# PIC32MK1024GPK064 device description
Architecture: MIPS; Family: PIC32MK; Series: PIC32MK
Registers are 32-bit, read-write, no defined reset value unless marked. A register's access mark holds for its fields unless they carry their own. Offsets are from the block's base; [hi:lo] are bit positions; {n}, {i} and the like mark numbered series; 'fields as' and 'values as' point back to an identical list.

## ADCHS
Instances: ADCHS 0x1f887000 in periph_pb5_std
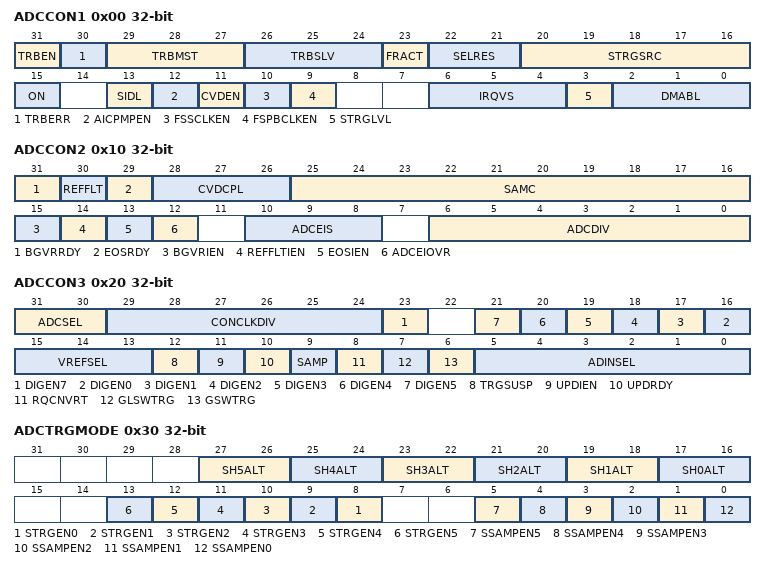
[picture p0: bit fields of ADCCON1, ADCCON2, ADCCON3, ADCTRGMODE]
0x00 ADCCON1 — ADC Control Register 1
  [31] TRBEN — Turbo Channel Enable bit
    1=Enable the Turbo channel; 0=Disable the Turbo channel
  [30] TRBERR — Turbo Channel Error Status bit
    1=An error occurred while setting the Turbo channel and Turbo channel function to be disabled regardless of the TRBEN bit being set to 1; 0=Turbo channel error did not occur
  [29:27] TRBMST — Turbo Master ADCx bits
    {v}=ADC{v} (v=0..5)
  [26:24] TRBSLV — Turbo Slave ADCx bits
    {v}=ADC{v} (v=0..5)
  [23] FRACT — Fractional Data Output Format bit
    1=Fractional; 0=Integer
  [22:21] SELRES — Shared ADC7 Resolution bits
    3=12 bits (default); 2=10 bits; 1=8 bits; 0=6 bits
  [20:16] STRGSRC — Scan Trigger Source Select bits
    30=PWM Generator 12 trigger (Motor Control only); 29=PWM Generator 11 trigger (Motor Control only); 28=PWM Generator 10 trigger (Motor Control only); {v}=PWM Generator {v-23} Current-Limit (Motor Control only) (v=24..27); 23=PWM Generator 9 trigger; 22=PWM Generator 8 trigger; 21=PWM Generator 7 trigger; 20=CTMU trip; {v}=Output Compare {v-15} period end (v=16..19); {v}=PWM Generator {v-9} trigger (Motor Control only) (v=10..15); 9=Secondary PWM time base (Motor Control only); 8=Primary PWM time base (Motor Control only); 7=General Purpose Timer5; 6=General Purpose Timer3; 5=General Purpose Timer1; 4=INT0; 3=Scan trigger; 2=Software level trigger; 1=Software edge trigger; 0=No Trigger
  [15] ON — ADC Module Enable bit
    1=ADC module is enabled; 0=ADC module is disabled
  [13] SIDL — Stop in Idle Mode bit
    1=Discontinue module operation when device enters Idle mode; 0=Continue module operation in Idle mode
  [12] AICPMPEN — Analog Input Charge Pump Enable bit
    1=Analog input charge pump is enabled; 0=Analog input charge pump is disabled (default)
  [11] CVDEN — Capacitive Voltage Division Enable bit
    1=CVD operation is enabled; 0=CVD operation is disabled
  [10] FSSCLKEN — Fast Synchronous System Clock to ADC Control Clock bit
    1=Fast synchronous system clock to ADC control clock is enabled; 0=Fast synchronous system clock to ADC control clock is disabled
  [9] FSPBCLKEN — Fast Synchronous Peripheral Clock to ADC Control Clock bit
    1=Fast synchronous peripheral clock to ADC control clock is enabled; 0=Fast synchronous peripheral clock to ADC control clock is disabled
  [6:4] IRQVS — Interrupt Vector Shift bits
    {v}=Shift x left {v} bit position (v=0..7)
  [3] STRGLVL — Scan Trigger High Level/Positive Edge Sensitivity bit
    1=Scan trigger is high level sensitive. Once STRIG mode is selected the scan trigger will continue for all selected analog inputs; 0=Scan trigger is positive edge sensitive. Once STRIG mode is selected only a single scan trigger will be generated which will complete the scan of all selected analog inputs. (TRGSRCx in the ADCTRGx register)
  [2:0] DMABL — DMA to System RAM Buffer Length Size bits
    7=Allocates 128 locations in system memory to each analog input; 6=Allocates 64 locations in system memory to each analog input; 5=Allocates 32 locations in system memory to each analog input; 4=Allocates 16 locations in system memory to each analog input; 3=Allocates 8 locations in system memory to each analog input; 2=Allocates 4 locations in system memory to each analog input; 1=Allocates 2 locations in system memory to each analog input; 0=Allocates 1 location in system memory to each analog input
0x10 ADCCON2 — ADC Control Register 2
  [31] BGVRRDY — Band Gap Voltage/ADC Reference Voltage Status bit
    1=Both band gap voltage and ADC reference voltages (Vref) are ready; 0=Either or both band gap voltage and ADC reference voltages (Vref) are not ready
  [30] REFFLT — Band Gap/ Vref / AVdd BOR Fault Status bit
    1=Fault in band gap or the Vref voltage while the ON bit (ADCCON1) was set. Most likely a band gap or Vref fault will be caused by a BOR of the analog Vdd supply.; 0=Band gap and Vref voltage are working properly
  [29] EOSRDY — End of Scan Interrupt Status bit
    1=All analog inputs are considered for scanning through the scan trigger (all analog inputs specified in the ADCCSS1 and ADCCSS2 registers) have completed scanning; 0=Scanning has not completed
  [28:26] CVDCPL — Capacitor Voltage Divider Setting bits
    7=7 * 2.5 pF = 17.5 pF; 6=6 * 2.5 pF = 15 pF; 5=5 * 2.5 pF = 12.5 pF; 4=4 * 2.5 pF = 10 pF; 3=3 * 2.5 pF = 7.5 pF; 2=2 * 2.5 pF = 5 pF; 1=1 * 2.5 pF = 2.5 pF; 0=0 * 2.5 pF = 0 pF
  [25:16] SAMC — Sample Time for the Shared ADC (ADC7) bits
    0x3ff=1025 Tad; 1=3 Tad; 0=2 Tad
  [15] BGVRIEN — Band Gap/ Vref Voltage Ready Interrupt Enable bit
    1=Interrupt will be generated when the BGVRDDY bit is set; 0=No interrupt is generated when the BGVRRDY bit is set
  [14] REFFLTIEN — Band Gap/ Vref Voltage Fault Interrupt Enable bit
    1=Interrupt will be generated when the REFFLT bit is set; 0=No interrupt is generated when the REFFLT bit is set
  [13] EOSIEN — End of Scan Interrupt Enable bit
    1=Interrupt will be generated when EOSRDY bit is set; 0=No interrupt is generated when the EOSRDY bit is set
  [12] ADCEIOVR — Early Interrupt Request Override bit
    1=Early interrupt generation is overridden and interrupt generation is controlled by the ADCGIRQEN1 and ADCGIRQEN2 registers; 0=Early interrupt generation is not overridden and interrupt generation is controlled by the ADCEIEN1 and ADCEIEN2 registers
  [10:8] ADCEIS — Shared ADC Early Interrupt Select bits
    {v}=The data ready interrupt is generated {v+1} ADC clocks prior to end of conversion (v=2..7); 1=The data ready interrupt is generated 2 ADC module clocks prior to end of conversion; 0=The data ready interrupt is generated 1 ADC module clock prior to end of conversion
  [6:0] ADCDIV — Shared ADC Clock Divider bits
    127=254 * Tq = Tad; 3=6 * Tq = Tad; 2=4 * Tq = Tad; 1=2 * Tq = Tad
0x20 ADCCON3 — ADC Control Register 3
  [31:30] ADCSEL — Analog-to-Digital Clock Source bits
    3=SYSCLK; 2=REFCLK3; 1=FRC; 0=SYSCLK
  [29:24] CONCLKDIV — Analog-to-Digital Control Clock Divider bits
    63=126 * Tclk = Tq; 3=6 * Tclk = Tq; 2=4 * Tclk = Tq; 1=2 * Tclk = Tq; 0=Tclk = Tq
  [23] DIGEN7 — Shared ADC (ADC7) Digital Enable bit
    1=ADC7 is digital enabled; 0=ADC7 is digital disabled
  [n+16] DIGEN{n} (n=0..5) — ADC{n} Digital Enable bit
    1=ADC{n} is digital enabled (required for active operation); 0=ADC{n} is digital disabled (power-saving mode)
  [15:13] VREFSEL — Voltage Reference Input Selection bits
    3=ADC VREFH is VREF+, ADC VREFL is VREF-; 2=ADC VREFH is AVDD, ADC VREFL is VREF-; 1=ADC VREFH is VREF+, ADC VREFL is AVSS; 0=ADC VREFH is AVDD, ADC VREFL is AVSS
  [12] TRGSUSP — Trigger Suspend bit
    1=Triggers are blocked from starting a new analog-to-digital conversion; 0=Triggers are not blocked
  [11] UPDIEN — Update Ready Interrupt Enable bit
    1=Interrupt will be generated when the UPDRDY bit is set by hardware; 0=No interrupt is generated
  [10] UPDRDY — ADC Update Ready Status bit
    1=ADC SFRs can be updated; 0=ADC SFRs cannot be updated
  [9] SAMP — Shared ADC7 Analog Input Sampling Enable bit
    1=The ADC S&H amplifier is sampling; 0=The ADC S&H amplifier is holding
  [8] RQCNVRT — Individual ADC Input Conversion Request bit
    1=Trigger the conversion of the selected ADC input as specified by the ADINSEL bits; 0=Do not trigger the conversion
  [7] GLSWTRG — Global Level Software Trigger bit
    1=Trigger conversion for ADC inputs that have selected the GLSWTRG bit as the trigger signal; 0=Do not trigger an analog-to-digital conversion
  [6] GSWTRG — Global Software Trigger bit
    1=Trigger conversion for ADC inputs that have selected the GSWTRG bit as either through the associated TRGSRC bits in the ADCTRGx registers or through the STRGSRC<4:0> bits in the ADCCON1 register the trigger signal; 0=Do not trigger an analog-to-digital conversion
  [5:0] ADINSEL — Analog Input Select bits
    53=CTMU Temperature Sensor (internal AN53); 52=VBAT/2 (internal AN52); 50=IVref 1.2V (internal AN50); {v}=AN{v} (v=45..49); {v}=AN{v} (v=33..41); {v}=AN{v} (v=0..27)
0x30 ADCTRGMODE — ADC Triggering Mode for Dedicated ADC Register
  [27:26] SH5ALT — ADC5 Analog Input Select bit
    3=AN25; 2=AN6; 1=AN2; 0=AN5
  [25:24] SH4ALT — ADC4 Analog Input Select bit
    3=AN0; 2=AN9; 1=AN1; 0=AN4
  [23:22] SH3ALT — ADC3 Analog Input Select bit
    3=AN26; 2=AN8; 1=AN0; 0=AN3
  [21:20] SH2ALT — ADC2 Analog Input Select bit
    3=AN25; 2=AN6; 1=AN5; 0=AN2
  [19:18] SH1ALT — ADC1 Analog Input Select bit
    3=AN0; 2=AN7; 1=AN4; 0=AN1
  [17:16] SH0ALT — ADC0 Analog Input Select bit
    3=AN24; 2=AN5; 1=AN3; 0=AN0
  [n+8] STRGEN{n} (n=0..5) — ADC{n} Presynchronized Triggers bit
    1=ADC{n} uses presynchronized triggers; 0=ADC{n} does not use presynchronized triggers
  [5] SSAMPEN5 — ADC5 Synchronous Sampling bit
    1=ADC5 uses synchronous sampling for the first sample after being idle or disabled; 0=ADC5 does not use synchronous sampling
  [4] SSAMPEN4 — ADC4 Synchronous Sampling bit
    1=ADC4 uses synchronous sampling for the first sample after being idle or disabled; 0=ADC4 does not use synchronous sampling
  [3] SSAMPEN3 — ADC3 Synchronous Sampling bit
    1=ADC3 uses synchronous sampling for the first sample after being idle or disabled; 0=ADC3 does not use synchronous sampling
  [2] SSAMPEN2 — ADC2Synchronous Sampling bit
    1=ADC2 uses synchronous sampling for the first sample after being idle or disabled; 0=ADC2 does not use synchronous sampling
  [1] SSAMPEN1 — ADC1 Synchronous Sampling bit
    1=ADC1 uses synchronous sampling for the first sample after being idle or disabled; 0=ADC1 does not use synchronous sampling
  [0] SSAMPEN0 — ADC0 Synchronous Sampling bit
    1=ADC0 uses synchronous sampling for the first sample after being idle or disabled; 0=ADC0 does not use synchronous sampling
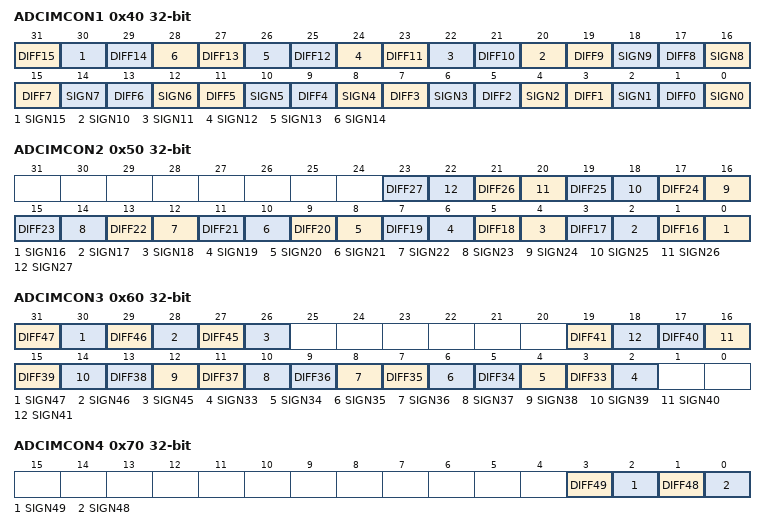
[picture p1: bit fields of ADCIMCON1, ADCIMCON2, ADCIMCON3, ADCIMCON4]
0x40 ADCIMCON1 — ADC Input Mode Control Register 1
  [2n+1] DIFF{n} (n=9..15) — AN{n} Mode bit
    1=Selects AN{n} differential input pair as AN{n}+ and AN1-; 0=AN{n} is using Single-ended mode
  [30] SIGN15 — NO_SUCH_FIELD
    1=AN15 is using Signed Data mode; 0=AN15 is using Unsigned Data mode
  [2n] SIGN{n} (n=0..14) — AN{n} Signed Data Mode bit
    1=AN{n} is using Signed Data mode; 0=AN{n} is using Unsigned Data mode
  [17] DIFF8 — AN 8 Mode bit
    1=Selects AN8 differential input pair as AN8+ and AN1-; 0=AN8 is using Single-ended mode
  [15] DIFF7 — AN7 Mode bit
    1=Selects AN7 differential input pair as AN7+ and AN1-; 0=AN7 is using Single-ended mode
  [13] DIFF6 — AN6 Mode bit
    1=Selects AN6 differential input pair as AN6+ and AN1-; 0=AN6 is using Single-ended mode
  [11] DIFF5 — AN5 Mode bit
    1=Selects AN5 differential input pair as AN5+ and AN11-; 0=AN5 is using Single-ended mode
  [9] DIFF4 — AN4 Mode bit
    1=Selects AN4 differential input pair as AN4+ and AN10-; 0=AN4 is using Single-ended mode
  [7] DIFF3 — AN3 Mode bit
    1=Selects AN3 differential input pair as AN3+ and AN27-; 0=AN3 is using Single-ended mode
  [5] DIFF2 — AN2 Mode bit
    1=Selects AN2 differential input pair as AN2+ and AN8-; 0=AN2 is using Single-ended mode
  [3] DIFF1 — AN1 Mode bit
    1=Selects AN1 differential input pair as AN1+ and AN7-; 0=AN1 is using Single-ended mode
  [1] DIFF0 — AN0 Mode bit
    1=Selects AN0 differential input pair as AN0+ and AN6-; 0=AN0 is using Single-ended mode
0x50 ADCIMCON2 — ADC Input Mode Control Register 2
  [2n-31] DIFF{n} (n=16..27) — AN{n} Mode bit
    1=Selects AN{n} differential pair input as AN{n}+ and AN1-; 0=AN{n} is using Single-ended mode
  [2n-32] SIGN{n} (n=16..27) — AN{n} Signed Data Mode bit
    values as ADCIMCON1.SIGN0
0x60 ADCIMCON3 — ADC Input Mode Control Register 3
  [31] DIFF47 — AN47 Mode bit
    1=Selects AN47 differential input pair as AN47+ and AN1-; 0=AN47 is using Single-ended mode
  [30] SIGN47 — AN47 Signed Data Mode bit
    1=AN41 is using Signed Data mode; 0=AN41 is using Unsigned Data mode
  [29] DIFF46 — AN46 Mode bit
    1=Selects AN46 differential input pair as AN46+ and AN1-; 0=AN41 is using Single-ended mode
  [28] SIGN46 — AN45 Signed Data Mode bit
    1=AN46 is using Signed Data mode; 0=AN46 is using Unsigned Data mode
  [27] DIFF45 — AN45 Mode bit
    1=Selects AN45 differential input pair as AN45+ and AN1-; 0=AN45 is using Single-ended mode
  [26] SIGN45 — NO_SUCH_FIELD
    1=AN45 is using Signed Data mode; 0=AN45 is using Unsigned Data mode
  [2n-63] DIFF{n} (n=33..41) — AN{n} Mode bit
    values as ADCIMCON1.DIFF9
  [2n-64] SIGN{n} (n=33..41) — AN{n} Signed Data Mode bit
    values as ADCIMCON1.SIGN0
0x70 ADCIMCON4 — ADC Input Mode Control Register 4
  [3] DIFF49 — AN49 Mode bit
    1=Selects AN49 differential input pair as AN49+ and AN1-; 0=AN49 is using Single-ended mode
  [2] SIGN49 — AN41 Signed Data Mode bit
    1=AN49 is using Signed Data mode; 0=AN49 is using Unsigned Data mode
  [1] DIFF48 — AN48 Mode bit
    1=Selects AN40 differential input pair as AN48+ and AN1-; 0=AN48 is using Single-ended mode
  [0] SIGN48 — AN48 Signed Data Mode bit
    1=AN48 is using Signed Data mode; 0=AN48 is using Unsigned Data mode
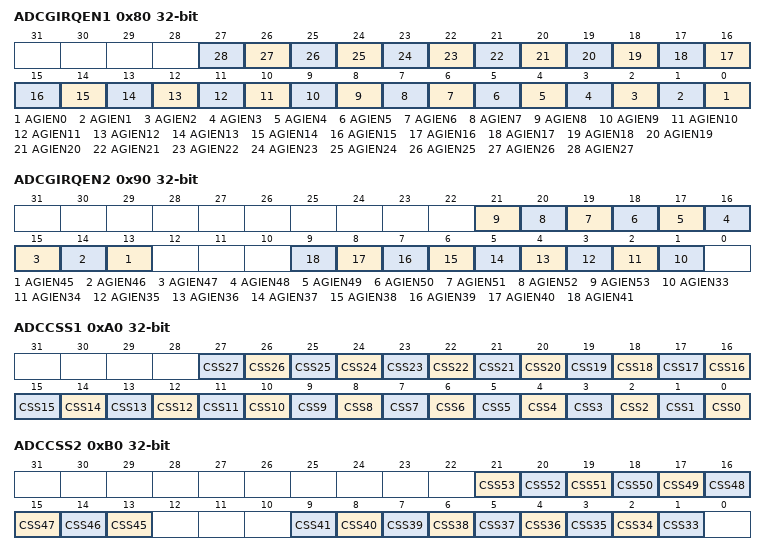
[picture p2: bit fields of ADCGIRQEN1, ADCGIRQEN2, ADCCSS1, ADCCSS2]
0x80 ADCGIRQEN1 — ADC Global Interrupt Enable Register 1
  [all] fields
    1=Interrupts are enabled for the selected analog input. The interrupt is generated after the converted data is ready (indicated by the AIRDYx bit of the ADCDSTAT1 register); 0=Interrupts are disabled
  [n] AGIEN{n} (n=0..27) — ADC Global Interrupt Enable bit
0x90 ADCGIRQEN2 — ADC Global Interrupt Enable Register 2
  [all] fields
    values as the fields of ADCGIRQEN1
  [n-32] AGIEN{n} (n=45..53) — ADC Global Interrupt Enable bit
  [n-32] AGIEN{n} (n=33..41) — ADC Global Interrupt Enable bit
0xA0 ADCCSS1 — ADC Common Scan Select Register 1
  [all] fields
    1=Select ANx for input scan (i.e.ANx = CSSx and scan is sequential starting with the lowest to highest enabled CSSx analog input pin); 0=Skip ANx for input scan
  [n] CSS{n} (n=0..27) — Analog Common Scan Select bits
0xB0 ADCCSS2 — ADC Common Scan Select Register 2
  [all] fields
    values as the fields of ADCCSS1
  [n-32] CSS{n} (n=45..53) — Analog Common Scan Select bits
  [n-32] CSS{n} (n=33..41) — Analog Common Scan Select bits
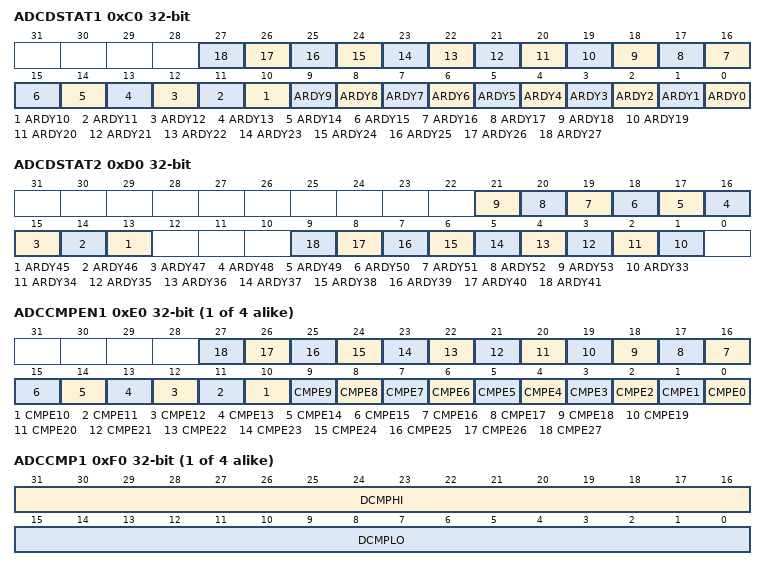
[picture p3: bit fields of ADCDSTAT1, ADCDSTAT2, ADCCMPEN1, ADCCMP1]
0xC0 ADCDSTAT1 ro — ADC Data Ready Status Register 1
  [all] fields
    1=This bit is set when converted data is ready in the data register; 0=This bit is cleared when the associated data register is read
  [n] ARDY{n} (n=0..27) — Conversion Data Ready for Corresponding Analog Input Ready bits
0xD0 ADCDSTAT2 ro — ADC Data Ready Status Register 2
  [all] fields
    values as the fields of ADCDSTAT1
  [n-32] ARDY{n} (n=45..53) — Conversion Data Ready for Corresponding Analog Input Ready bits
  [n-32] ARDY{n} (n=33..41) — Conversion Data Ready for Corresponding Analog Input Ready bits
{0xC0+0x20*i} ADCCMPEN{i} (i=1..4) — ADC Digital Comparator 'x' Enable Register ('x' = 1 through 4)
  [n] CMPE{n} (n=0..27)
{0xD0+0x20*i} ADCCMP{i} (i=1..4) — ADC Digital Comparator
  [31:16] DCMPHI, [15:0] DCMPLO
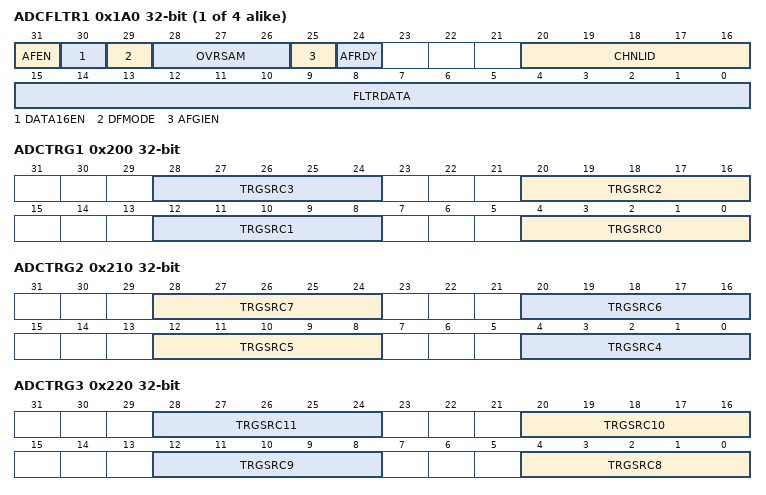
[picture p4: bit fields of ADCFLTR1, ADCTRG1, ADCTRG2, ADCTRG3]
{0x190+0x10*i} ADCFLTR{i} (i=1..4) — ADC Digital Filter Register
  [31] AFEN — Digital Filter 'x' Enable bit
    1=Digital filter is enabled; 0=Digital filter is disabled and the AFRDY status bit is cleared
  [30] DATA16EN — Filter Significant Data Length bit
    1=All 16 bits of the filter output data are significant; 0=Only the first 12 bits are significant
  [29] DFMODE — ADC Filter Mode bit
    1=Filter x works in Averaging mode; 0=Filter x works in Oversampling Filter mode (default)
  [28:26] OVRSAM — Oversampling Filter Ratio bits
    7=(If DFMODE is 0) 128 samples (shift sum 3 bits to right output data is in 15.1 format) / (If DFMODE is 1) 256 samples (256 samples to be averaged); 6=(If DFMODE is 0) 32 samples (shift sum 2 bits to right output data is in 14.1 format) / (If DFMODE is 1) 128 samples (128 samples to be averaged); 5=(If DFMODE is 0) 8 samples (shift sum 1 bit to right output data is in 13.1 format) / (If DFMODE is 1) 64 samples (64 samples to be averaged); 4=(If DFMODE is 0) 2 samples (shift sum 0 bits to right output data is in 12.1 format) / (If DFMODE is 1) 32 samples (32 samples to be averaged); 3=(If DFMODE is 0) 256 samples (shift sum 4 bits to right output data is 16 bits) / (If DFMODE is 1) 16 samples (16 samples to be averaged); 2=(If DFMODE is 0) 64 samples (shift sum 3 bits to right output data is 15 bits) / (If DFMODE is 1) 8 samples (8 samples to be averaged); 1=(If DFMODE is 0) 16 samples (shift sum 2 bits to right output data is 14 bits) / (If DFMODE is 1) 4 samples (4 samples to be averaged); 0=(If DFMODE is 0) 4 samples (shift sum 1 bit to right output data is 13 bits) / (If DFMODE is 1) 2 samples (2 samples to be averaged)
  [25] AFGIEN — Digital Filter 'x' Interrupt Enable bit
    1=Digital filter interrupt is enabled and is generated by the AFRDY status bit; 0=Digital filter is disabled
  [24] AFRDY — Digital Filter 'x' Data Ready Status bit
    1=Data is ready in the FLTRDATA bits; 0=Data is not ready
  [20:16] CHNLID — Digital Filter Analog Input Selection bits
    {v}=AN{v} input (v=24..27); {v}=AN{v}(1) input (v=20..23); {v}=AN{v} input (v=6..19); {v}=ADC{v} Module (v=0..5)
  [15:0] FLTRDATA
0x200 ADCTRG1 — ADC Trigger Source 1 Register
  [all] fields
    30=PWM Generator 12 trigger (Motor control only); 29=PWM Generator 11 trigger (Motor control only); 28=PWM Generator 10 trigger (Motor control only); {v}=PWM Generator {v-23} Current-Limit (Motor Control Variants Only) (v=24..27); 23=PWM Generator 9 trigger; 22=PWM Generator 8 trigger; 21=PWM Generator 7 trigger; 20=CTMU trip; {v}=Output Compare {v-15} period end (v=16..19); {v}=PWM Generator {v-9} trigger (Motor Control Variants Only) (v=10..15); 9=Secondary Special time base (Motor Control Variants Only); 8=Primary Special Event time base (Motor Control Variants Only); 7=General Purpose Timer5; 6=General Purpose Timer3; 5=General Purpose Timer1; 4=INT0; 3=Scan trigger (see Note); 2=Software level trigger; 1=Software edge trigger; 0=No Trigger
  [8n+4:8n] TRGSRC{n} (n=0..3) — Trigger Source for Conversion of ADC{n} Module Select bits
0x210 ADCTRG2 — ADC Trigger Source 2 Register
  [all] fields
    30=PWM Generator 12 trigger (Motor Control Only); 29=PWM Generator 11 trigger (Motor Control Only); 28=PWM Generator 10 trigger (Motor Control Only); {v}=PWM Generator {v-23} Current-Limit (Motor Control Variants Only) (v=24..27); 23=PWM Generator 9 trigger; 22=PWM Generator 8 trigger; 21=PWM Generator 7 trigger; 20=CTMU trip; {v}=Output Compare {v-15} (Rising Edge Only) (v=16..19); {v}=PWM Generator {v-9} trigger (Motor Control Variants Only) (v=10..15); 9=Secondary Special time base (Motor Control Variants Only); 8=Primary PWM time base (Motor Control Variants Only); 7=General Purpose Timer5; 6=General Purpose Timer3; 5=General Purpose Timer1; 4=INT0; 3=Scan trigger (see Note); 2=Software level trigger; 1=Software edge trigger; 0=No Trigger
  [28:24] TRGSRC7 — Trigger Source for Conversion of Analog Input AN7 Select bits
  [20:16] TRGSRC6 — Trigger Source for Conversion of Analog Input AN6 Select bits
  [12:8] TRGSRC5 — Trigger Source for Conversion of ADC5 Module Select bits
  [4:0] TRGSRC4 — Trigger Source for Conversion of ADC4 Module Select bits
0x220 ADCTRG3 — ADC Trigger Source 3 Register
  [all] fields
    30=PWM Generator 12 trigger (Motor control only); 29=PWM Generator 11 trigger (Motor control only); 28=PWM Generator 10 trigger (Motor control only); {v}=PWM Generator {v-23} Current-Limit (Motor Control only) (v=24..27); 23=PWM Generator 9 trigger; 22=PWM Generator 8 trigger; 21=PWM Generator 7 trigger; 20=CTMU trip; {v}=Output Compare {v-15} (Rising Edge Only) (v=16..19); {v}=PWM Generator {v-9} trigger (Motor Control only) (v=10..15); 9=Secondary PWM time base (Motor Control only); 8=Primary PWM time base (Motor Control only); 7=General Purpose Timer5; 6=General Purpose Timer3; 5=General Purpose Timer1; 4=INT0; 3=Scan trigger (see Note); 2=Software level trigger; 1=Software edge trigger; 0=No Trigger
  [8n-60:8n-64] TRGSRC{n} (n=8..11) — Trigger Source for Conversion of Analog Input AN{n} Select bits
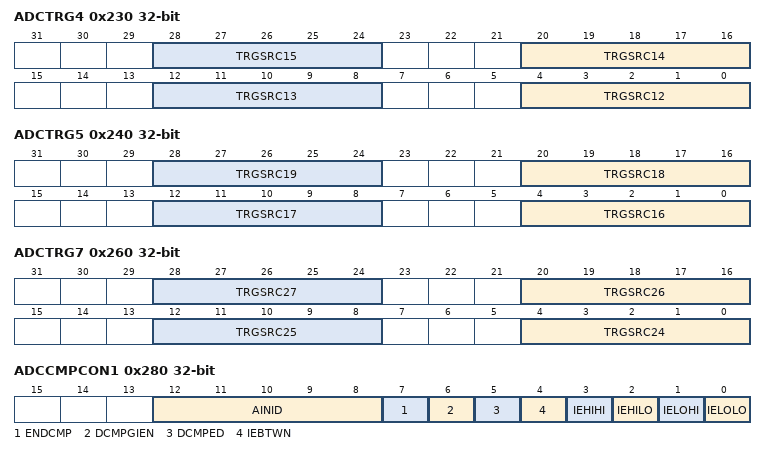
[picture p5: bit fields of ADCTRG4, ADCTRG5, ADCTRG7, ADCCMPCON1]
0x230 ADCTRG4 — ADC Trigger Source 4 Register
  [all] fields
    30=PWM Generator 12 trigger; 29=PWM Generator 11 trigger; 28=PWM Generator 10 trigger; {v}=PWM Generator {v-23} Current-Limit (Motor Control only) (v=24..27); 23=PWM Generator 9 trigger; 22=PWM Generator 8 trigger; 21=PWM Generator 7 trigger; 20=CTMU trip; {v}=Output Compare {v-15} (Rising Edge Only) (v=16..19); {v}=PWM Generator {v-9} trigger (Motor Control only) (v=10..15); 9=Secondary PWM time base (Motor Control only); 8=Primary PWM time base (Motor Control only); 7=General Purpose Timer5; 6=General Purpose Timer3; 5=General Purpose Timer1; 4=INT0; 3=Scan trigger (see Note); 2=Software level trigger; 1=Software edge trigger; 0=No Trigger
  [8n-92:8n-96] TRGSRC{n} (n=12..15) — Trigger Source for Conversion of Analog Input AN{n} Select bits
0x240 ADCTRG5 — ADC Trigger Source 5 Register
  [all] fields
    30=PWM Generator 12 trigger (Motor control only); 29=PWM Generator 11 trigger (Motor control only); 28=PWM Generator 10 trigger (Motor control only); {v}=PWM Generator {v-23} Current-Limit (Motor Control only) (v=24..27); 23=PWM Generator 9 trigger; 22=PWM Generator 8 trigger; 21=PWM Generator 7 trigger; 20=CTMU trip; {v}=Output Compare {v-15} (Rising Edge only) (v=16..19); {v}=PWM Generator {v-9} trigger (Motor Control only) (v=10..15); 9=Secondary PWM time base (Motor Control only); 8=Primary PWM time base (Motor Control only); 7=General Purpose Timer5; 6=General Purpose Timer3; 5=General Purpose Timer1; 4=INT0; 3=Scan trigger (see Note); 2=Software level trigger; 1=Software edge trigger; 0=No Trigger
  [8n-124:8n-128] TRGSRC{n} (n=16..19) — Trigger Source for Conversion of Analog Input AN{n} Select bits
0x260 ADCTRG7 — ADC Trigger Source 7 Register
  [all] fields
    30=PWM Generator 12 trigger (Motor control only); 29=PWM Generator 11 trigger (Motor control only); 28=PWM Generator 10 trigger (Motor control only); {v}=PWM Generator {v-23} Current-Limit (Motor Control only) (v=24..27); 23=PWM Generator 9 trigger; 22=PWM Generator 8 trigger; 21=PWM Generator 7 trigger; 20=CTMU trip; {v}=Output Compare {v-15} (Rising Edge only) (v=16..19); {v}=PWM Generator {v-9} trigger (Motor Control only) (v=10..15); 9=Secondary PWM time base (Motor Control only); 8=Primary PWM time base (Motor Control only); 7=General Purpose Timer5; 6=General Purpose Timer3; 5=General Purpose Timer1; 4=INT0; 3=Scan trigger (see the following Note); 2=Software level trigger; 1=Software edge trigger; 0=No Trigger
  [8n-188:8n-192] TRGSRC{n} (n=24..27) — Trigger Source for Conversion of Analog Input AN{n} Select bits
0x280 ADCCMPCON1 — ADC Digital Comparator 1 Control Register
  [12:8] AINID — Digital Comparator 'x' Analog Input Identification bits
    {v}=AN{v} (v=0..27)
  [7] ENDCMP — Digital Comparator 'x' Enable bit
    1=Digital Comparator 1 is enabled; 0=Digital Comparator 1 is not enabled
  [6] DCMPGIEN — Digital Comparator 'x' Global Interrupt Enable bit
    1=A Digital Comparator 1 interrupt is generated when the DCMPED status bit (ADCCMPxCON) is set; 0=A Digital Comparator 1 interrupt is disabled
  [5] DCMPED — Digital Comparator 'x' "Output True" Event Status bit
    1=Digital Comparator 1 output true event has occurred (output of Comparator is 1); 0=Digital Comparator 1 output is false (output of Comparator is 0)
  [4] IEBTWN — Between Low/High Digital Comparator x Event bit
    1=Generate a digital comparator event when the DCMPLO bits less than DATA bits less than DCMPHI bits; 0=Do not generate an event
  [3] IEHIHI — High/High Digital Comparator x Event bit
    1=Generate a Digital Comparator 1 Event when the DCMPHI bits less than or equal to DATA(31:0) bits; 0=Do not generate an event
  [2] IEHILO — High/Low Digital Comparator x Event bit
    1=Generate a Digital Comparator 1 Event when the DATA bits less than DCMPHI(15:0) bits; 0=Do not generate an event
  [1] IELOHI — Low/High Digital Comparator x Event bit
    1=Generate a Digital Comparator 1 Event when the DCMPLO bits less than DATA(31:0) bits; 0=Do not generate an event
  [0] IELOLO — Low/Low Digital Comparator x Event bit
    1=Generate a Digital Comparator 1 Event when the DATA bits less than DCMPLO(15:0) bits; 0=Do not generate an event
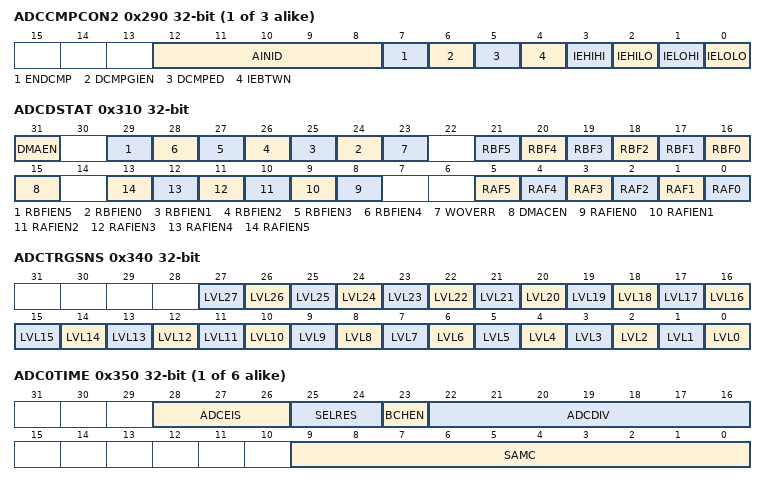
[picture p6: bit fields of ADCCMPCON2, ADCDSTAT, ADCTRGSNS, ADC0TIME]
{0x270+0x10*i} ADCCMPCON{i} (i=2..4) — ADC Digital Comparator 2 Control Register
  [12:8] AINID — Digital Comparator 'x' Analog Input Identification bits
    {v}=AN{v} (v=0..27)
  [7] ENDCMP — Digital Comparator 'x' Enable bit
    1=Digital Comparator {i} is enabled; 0=Digital Comparator {i} is not enabled
  [6] DCMPGIEN — Digital Comparator 'x' Global Interrupt Enable bit
    1=A Digital Comparator {i} interrupt is generated when the DCMPED status bit (ADCCMPxCON) is set; 0=A Digital Comparator {i} interrupt is disabled
  [5] DCMPED — Digital Comparator 'x' "Output True" Event Status bit
    1=Digital Comparator {i} output true event has occurred (output of Comparator is 1); 0=Digital Comparator {i} output is false (output of Comparator is 0)
  [4] IEBTWN — Between Low/High Digital Comparator x Event bit
    values as ADCCMPCON1.IEBTWN
  [3] IEHIHI — High/High Digital Comparator x Event bit
    1=Generate a Digital Comparator {i} Event when the DCMPHI bits less than or equal to DATA(31:0) bits; 0=Do not generate an event
  [2] IEHILO — High/Low Digital Comparator x Event bit
    1=Generate a Digital Comparator {i} Event when the DATA bits less than DCMPHI(15:0) bits; 0=Do not generate an event
  [1] IELOHI — Low/High Digital Comparator x Event bit
    1=Generate a Digital Comparator {i} Event when the DCMPLO bits less than DATA(31:0) bits; 0=Do not generate an event
  [0] IELOLO — Low/Low Digital Comparator x Event bit
    1=Generate a Digital Comparator {i} Event when the DATA bits less than DCMPLO(15:0) bits; 0=Do not generate an event
0x300 ADCBASE
  [15:0] ADCBASE — ADC ISR Base Address bits
    0=Base address is 0
0x310 ADCDSTAT — ADC DMA Status Register
  [31] DMAEN — Global ADC DMA Enable bit
    1=DMA interface is enabled; 0=DMA interface is disabled
  [29] RBFIEN5
  [n+24] RBFIEN{n} (n=0..4) — RAM DMA Buffer B Full Interrupt Enable bits for ADC{n}
    1=Enable ping-pong DMA Buffer B interrupt requests for ADC5-ADC0; 0=Disable ping-pong DMA Buffer B interrupt requests for ADC5-ADC0
  [23] WOVERR
  [n+16] RBF{n} (n=0..5) — RAM DMA Buffer B Full Status bits for ADC{n}
    1=RAM DMA ping-pong Buffer B is full; 0=RAM DMA pin-pong Buffer B is not full
  [15] DMACEN
  [n+8] RAFIEN{n} (n=0..5) — RAM DMA Buffer A Full Interrupt Enable bits for ADC{n}
    1=Enable ping-pong DMA Buffer A interrupt requests for ADC; 0=Disable ping-pong DMA Buffer A interrupt requests for ADC
  [n] RAF{n} (n=0..5) — RAM DMA Ping-Pong Buffer A Full Status bits for ADC{n}
    1=RAM DMA ping-pong Buffer A is full; 0=RAM DMA ping-pong Buffer A is not full
0x320 ADCCNTB — ADC Channel Sample Count Base Address Register
0x330 ADCDMAB — ADC Channel Sample Count Base Address Register
0x340 ADCTRGSNS — ADC Trigger Level/Edge Sensitivity Register
  [all] fields
    1=Analog input is sensitive to the high level of its trigger (level sensitivity implies retriggering as long as the trigger signal remains high); 0=Analog input is sensitive to the positive edge of its trigger (this is the value after a reset)
  [n] LVL{n} (n=0..27) — Trigger Level and Edge Sensitivity bits
{0x350+0x10*i} ADC{i}TIME (i=0..5) — Dedicated High-Speed ADCx Timing Register {i}
  [28:26] ADCEIS — ADCx Early Interrupt Select bits
    {v}=The data ready interrupt is generated {v+1} ADC clocks prior to the end of conversion (v=1..7); 0=The data ready interrupt is generated 1 ADC clock prior to the end of conversion
  [25:24] SELRES — ADCx Resolution Select bits
    3=12 bits; 2=10 bits; 1=8 bits; 0=6 bits
  [23] BCHEN — Buffer Channel Enable bit
    1=ADC data saved in DMA system ram buffer when DMAEN (ADCDSTAT) = 1; 0=ADC data must be read by CPU from appropriate ADC result register
  [22:16] ADCDIV — ADCx Clock Divisor bits
    127=254 * TQ = TADx; 3=6 * TQ = TADx; 2=4 * TQ = TADx; 1=2 * TQ = TADx
  [9:0] SAMC — ADCx Sample Time bits
    0x3ff=1025 TADx; 1=3 TADx; 0=2 TADx
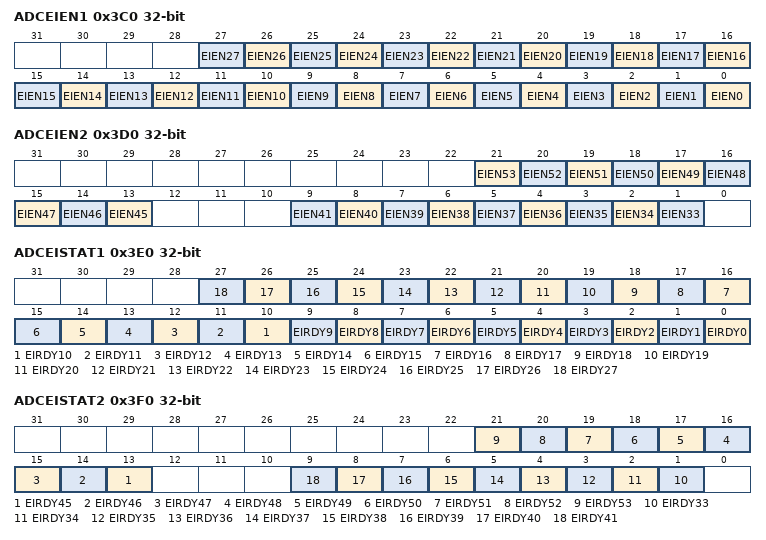
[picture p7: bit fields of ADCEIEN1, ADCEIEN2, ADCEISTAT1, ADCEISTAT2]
0x3C0 ADCEIEN1 — ADC Early Interrupt Enable Register 1
  [all] fields
    1=Early Interrupts are enabled for the selected analog input. The interrupt is generated after the early interrupt event occurs; 0=Interrupts are disabled
  [n] EIEN{n} (n=0..27) — Early Interrupt Enable for Analog Input bits
0x3D0 ADCEIEN2 — ADC Early Interrupt Enable Register 2
  [all] fields
    values as the fields of ADCEIEN1
  [n-32] EIEN{n} (n=45..53) — Early Interrupt Enable for Analog Input bits
  [n-32] EIEN{n} (n=33..41) — Early Interrupt Enable for Analog Input bits
0x3E0 ADCEISTAT1 ro — ADC Early Interrupt Status Register 1
  [all] fields
    1=This bit is set when the early interrupt event occurs for the specified analog input. An interrupt will be generated if early interrupts are enabled in the ADCEIEN1 register. For the Class 1 analog inputs this bit will set as per the configuration of the ADCEIS bits in the ADCxTIME register. For the shared ADC module this bit will be set as per the configuration of the ADCEIS<2:0> bits in the ADCCON2 register.; 0=Interrupts are disabled
  [n] EIRDY{n} (n=0..27) — Early Interrupt for Corresponding Analog Input Ready bits
0x3F0 ADCEISTAT2 — ADC Early Interrupt Status Register 2
  [all] fields
    values as the fields of ADCEISTAT1
  [n-32] EIRDY{n} (n=45..53) — Early Interrupt for Corresponding Analog Input Ready bits
  [n-32] EIRDY{n} (n=33..41) — Early Interrupt for Corresponding Analog Input Ready bits
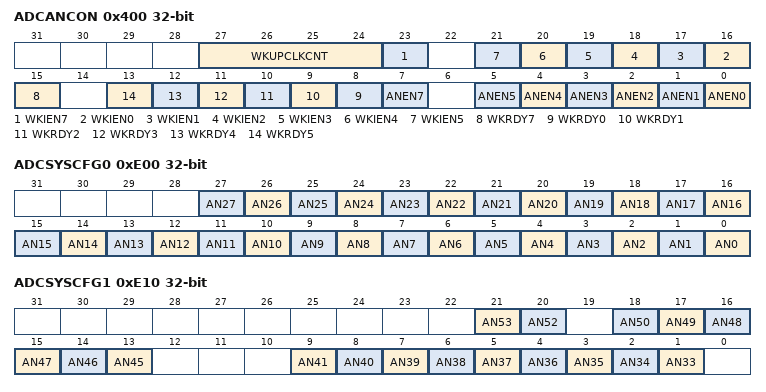
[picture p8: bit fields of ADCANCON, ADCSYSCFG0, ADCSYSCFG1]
0x400 ADCANCON — ADC Analog Warm-up Control Register
  [27:24] WKUPCLKCNT — Wake-up Clock Count bits
    15=2^15 = 32768 clocks; 14=2^14 = 16384 clocks; 13=2^13 = 8192 clocks; 12=2^12 = 4096 clocks; 11=2^11 = 2048 clocks; 10=2^10 = 1024 clocks; 9=2^9 = 512 clocks; 8=2^8 = 256 clocks; 7=2^7 = 128 clocks; 6=2^6 = 64 clocks; 5=2^5 = 32 clocks; 0=2^4 = 16 clocks
  [23] WKIEN7 — Shared ADC Wake-up Interrupt Enable bit
    1=Enable interrupt and generate interrupt when the WKRDY7 status bit is set; 0=Disable interrupt
  [n+16] WKIEN{n} (n=0..5) — ADC Wake-up Interrupt Enable bit
    1=Enable interrupt and generate interrupt when the WKRDYx status bit is set; 0=Disable interrupt
  [15] WKRDY7 — Shared ADC Wake-up Status bit
    1=ADC7 Analog and Bias circuitry ready after the wake-up count number 2WKUPEXP clocks after setting ANEN7 to 1; 0=ADC7 Analog and Bias circuitry is not ready
  [n+8] WKRDY{n} (n=0..5) — ADC5-ADC0 Wake-up Status bit
    1=ADCx Analog and Bias circuitry ready after the wake-up count number 2WKUPEXP clocks after setting ANENx to 1; 0=ADCx Analog and Bias circuitry is not ready
  [7] ANEN7 — Shared ADC Analog and Bias Circuitry Enable bit
    1=Analog and bias circuitry enabled. Once the analog and bias circuit is enabled the ADC module needs a warm-up time as defined by the WKUPCLKCNT bits.; 0=Analog and bias circuitry disabled
  [n] ANEN{n} (n=0..5) — ADC Analog and Bias Circuitry Enable bits
    values as ANEN7
{0x600+0x10*i} ADCDATA{i} (i=0..21) — ADC Output Data Register
  [31:0] DATA
{0x600+0x10*i} ADCDATA{i} (i=24..27) — ADC Output Data Register
  [31:0] DATA
0x810 ADCDATA33 — ADC Output Data Register
  [31:0] DATA
0x820 ADCDATA34 — ADC Output Data Register
  [31:0] DATA
0x890 ADCDATA51 — ADC Output Data Register
  [31:0] DATA
0x8D0 ADCDATA45 — ADC Output Data Register
  [31:0] DATA
0x8E0 ADCDATA46 — ADC Output Data Register
  [31:0] DATA
{0x600+0x10*i} ADCDATA{i} (i=48..50) — ADC Output Data Register
  [31:0] DATA
0x940 ADCDATA52 — ADC Output Data Register
  [31:0] DATA
0x950 ADCDATA53 — ADC Output Data Register
  [31:0] DATA
{0xD00+0x10*i} ADC{i}CFG (i=0..5) — ADC{i} Configuration Register
  [31:0] ADCCFG
0xD60 ADC7CFG
  [31:0] ADCCFG
0xE00 ADCSYSCFG0 ro — ADC System Configuration Register 0
  [n] AN{n} (n=0..27)
0xE10 ADCSYSCFG1 ro — ADC System Configuration Register 1
  [21] AN53, [20] AN52, [n-32] AN{n} (n=45..50), [n-32] AN{n} (n=33..41)

## Notices in the file
Copyright (c) 2019 Microchip Technology Inc.
SPDX-License-Identifier: Apache-2.0
Licensed under the Apache License, Version 2.0 (the "License");
you may not use this file except in compliance with the License.
You may obtain a copy of the License at
http://www.apache.org/licenses/LICENSE-2.0
Unless required by applicable law or agreed to in writing, software
distributed under the License is distributed on an "AS IS" BASIS,
WITHOUT WARRANTIES OR CONDITIONS OF ANY KIND, either express or implied.
See the License for the specific language governing permissions and
limitations under the License.
